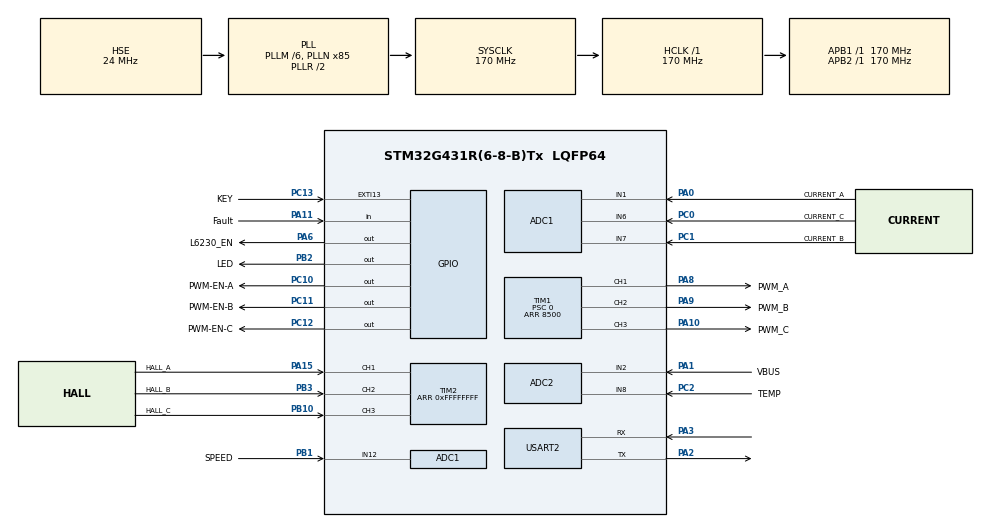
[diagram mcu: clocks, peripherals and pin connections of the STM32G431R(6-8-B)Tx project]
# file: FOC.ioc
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ADC1.Channel-0\#ChannelRegularConversion=ADC_CHANNEL_1
ADC1.Channel-1\#ChannelRegularConversion=ADC_CHANNEL_7
ADC1.Channel-2\#ChannelRegularConversion=ADC_CHANNEL_6
ADC1.Channel-3\#ChannelRegularConversion=ADC_CHANNEL_12
ADC1.ContinuousConvMode=DISABLE
ADC1.DMAContinuousRequests=ENABLE
ADC1.EOCSelection=ADC_EOC_SEQ_CONV
ADC1.ExternalTrigConv=ADC_EXTERNALTRIG_T1_TRGO
ADC1.NbrOfConversion=4
ADC1.NbrOfConversionFlag=1
ADC1.OffsetNumber-0\#ChannelRegularConversion=ADC_OFFSET_NONE
ADC1.OffsetNumber-1\#ChannelRegularConversion=ADC_OFFSET_NONE
ADC1.OffsetNumber-2\#ChannelRegularConversion=ADC_OFFSET_NONE
ADC1.OffsetNumber-3\#ChannelRegularConversion=ADC_OFFSET_NONE
ADC1.Rank-0\#ChannelRegularConversion=1
ADC1.Rank-1\#ChannelRegularConversion=2
ADC1.Rank-2\#ChannelRegularConversion=3
ADC1.Rank-3\#ChannelRegularConversion=4
ADC1.SamplingTime-0\#ChannelRegularConversion=ADC_SAMPLETIME_6CYCLES_5
ADC1.SamplingTime-1\#ChannelRegularConversion=ADC_SAMPLETIME_6CYCLES_5
ADC1.SamplingTime-2\#ChannelRegularConversion=ADC_SAMPLETIME_6CYCLES_5
ADC1.SamplingTime-3\#ChannelRegularConversion=ADC_SAMPLETIME_6CYCLES_5
ADC1.master=1
ADC2.Channel-0\#ChannelRegularConversion=ADC_CHANNEL_2
ADC2.Channel-1\#ChannelRegularConversion=ADC_CHANNEL_8
ADC2.DMAContinuousRequests=ENABLE
ADC2.EOCSelection=ADC_EOC_SEQ_CONV
ADC2.ExternalTrigConv=ADC_EXTERNALTRIG_T1_TRGO
ADC2.NbrOfConversion=2
ADC2.NbrOfConversionFlag=1
ADC2.OffsetNumber-0\#ChannelRegularConversion=ADC_OFFSET_NONE
ADC2.OffsetNumber-1\#ChannelRegularConversion=ADC_OFFSET_NONE
ADC2.Rank-0\#ChannelRegularConversion=1
ADC2.Rank-1\#ChannelRegularConversion=2
ADC2.SamplingTime-0\#ChannelRegularConversion=ADC_SAMPLETIME_6CYCLES_5
ADC2.SamplingTime-1\#ChannelRegularConversion=ADC_SAMPLETIME_6CYCLES_5
Dma.ADC1.0.Direction=DMA_PERIPH_TO_MEMORY
Dma.ADC1.0.EventEnable=DISABLE
Dma.ADC1.0.Instance=DMA1_Channel1
Dma.ADC1.0.MemDataAlignment=DMA_MDATAALIGN_WORD
Dma.ADC1.0.MemInc=DMA_MINC_ENABLE
Dma.ADC1.0.Mode=DMA_CIRCULAR
Dma.ADC1.0.PeriphDataAlignment=DMA_PDATAALIGN_WORD
Dma.ADC1.0.PeriphInc=DMA_PINC_DISABLE
Dma.ADC1.0.Polarity=HAL_DMAMUX_REQ_GEN_RISING
Dma.ADC1.0.Priority=DMA_PRIORITY_LOW
Dma.ADC1.0.RequestNumber=1
Dma.ADC1.0.SignalID=NONE
Dma.ADC1.0.SyncEnable=DISABLE
Dma.ADC1.0.SyncPolarity=HAL_DMAMUX_SYNC_NO_EVENT
Dma.ADC1.0.SyncRequestNumber=1
Dma.ADC1.0.SyncSignalID=NONE
Dma.ADC2.1.Direction=DMA_PERIPH_TO_MEMORY
Dma.ADC2.1.EventEnable=DISABLE
Dma.ADC2.1.Instance=DMA1_Channel2
Dma.ADC2.1.MemDataAlignment=DMA_MDATAALIGN_WORD
Dma.ADC2.1.MemInc=DMA_MINC_ENABLE
Dma.ADC2.1.Mode=DMA_CIRCULAR
Dma.ADC2.1.PeriphDataAlignment=DMA_PDATAALIGN_WORD
Dma.ADC2.1.PeriphInc=DMA_PINC_DISABLE
Dma.ADC2.1.Polarity=HAL_DMAMUX_REQ_GEN_RISING
Dma.ADC2.1.Priority=DMA_PRIORITY_LOW
Dma.ADC2.1.RequestNumber=1
Dma.ADC2.1.SignalID=NONE
Dma.ADC2.1.SyncEnable=DISABLE
Dma.ADC2.1.SyncPolarity=HAL_DMAMUX_SYNC_NO_EVENT
Dma.ADC2.1.SyncRequestNumber=1
Dma.ADC2.1.SyncSignalID=NONE
Dma.CORDIC_READ.3.Direction=DMA_PERIPH_TO_MEMORY
Dma.CORDIC_READ.3.EventEnable=DISABLE
Dma.CORDIC_READ.3.Instance=DMA1_Channel4
Dma.CORDIC_READ.3.MemDataAlignment=DMA_MDATAALIGN_WORD
Dma.CORDIC_READ.3.MemInc=DMA_MINC_ENABLE
Dma.CORDIC_READ.3.Mode=DMA_NORMAL
Dma.CORDIC_READ.3.PeriphDataAlignment=DMA_PDATAALIGN_WORD
Dma.CORDIC_READ.3.PeriphInc=DMA_PINC_DISABLE
Dma.CORDIC_READ.3.Polarity=HAL_DMAMUX_REQ_GEN_RISING
Dma.CORDIC_READ.3.Priority=DMA_PRIORITY_LOW
Dma.CORDIC_READ.3.RequestNumber=1
Dma.CORDIC_READ.3.SignalID=NONE
Dma.CORDIC_READ.3.SyncEnable=DISABLE
Dma.CORDIC_READ.3.SyncPolarity=HAL_DMAMUX_SYNC_NO_EVENT
Dma.CORDIC_READ.3.SyncRequestNumber=1
Dma.CORDIC_READ.3.SyncSignalID=NONE
Dma.CORDIC_WRITE.4.Direction=DMA_MEMORY_TO_PERIPH
Dma.CORDIC_WRITE.4.EventEnable=DISABLE
Dma.CORDIC_WRITE.4.Instance=DMA1_Channel5
Dma.CORDIC_WRITE.4.MemDataAlignment=DMA_MDATAALIGN_WORD
Dma.CORDIC_WRITE.4.MemInc=DMA_MINC_ENABLE
Dma.CORDIC_WRITE.4.Mode=DMA_NORMAL
Dma.CORDIC_WRITE.4.PeriphDataAlignment=DMA_PDATAALIGN_WORD
Dma.CORDIC_WRITE.4.PeriphInc=DMA_PINC_DISABLE
Dma.CORDIC_WRITE.4.Polarity=HAL_DMAMUX_REQ_GEN_RISING
Dma.CORDIC_WRITE.4.Priority=DMA_PRIORITY_LOW
Dma.CORDIC_WRITE.4.RequestNumber=1
Dma.CORDIC_WRITE.4.SignalID=NONE
Dma.CORDIC_WRITE.4.SyncEnable=DISABLE
Dma.CORDIC_WRITE.4.SyncPolarity=HAL_DMAMUX_SYNC_NO_EVENT
Dma.CORDIC_WRITE.4.SyncRequestNumber=1
Dma.CORDIC_WRITE.4.SyncSignalID=NONE
Dma.Request0=ADC1
Dma.Request1=ADC2
Dma.Request2=USART2_TX
Dma.Request3=CORDIC_READ
Dma.Request4=CORDIC_WRITE
Dma.USART2_TX.2.Direction=DMA_MEMORY_TO_PERIPH
Dma.USART2_TX.2.EventEnable=DISABLE
Dma.USART2_TX.2.Instance=DMA1_Channel3
Dma.USART2_TX.2.MemDataAlignment=DMA_MDATAALIGN_BYTE
Dma.USART2_TX.2.MemInc=DMA_MINC_ENABLE
Dma.USART2_TX.2.Mode=DMA_NORMAL
Dma.USART2_TX.2.PeriphDataAlignment=DMA_PDATAALIGN_BYTE
Dma.USART2_TX.2.PeriphInc=DMA_PINC_DISABLE
Dma.USART2_TX.2.Polarity=HAL_DMAMUX_REQ_GEN_RISING
Dma.USART2_TX.2.Priority=DMA_PRIORITY_LOW
Dma.USART2_TX.2.RequestNumber=1
Dma.USART2_TX.2.SignalID=NONE
Dma.USART2_TX.2.SyncEnable=DISABLE
Dma.USART2_TX.2.SyncPolarity=HAL_DMAMUX_SYNC_NO_EVENT
Dma.USART2_TX.2.SyncRequestNumber=1
Dma.USART2_TX.2.SyncSignalID=NONE
Mcu.Family=STM32G4
Mcu.Name=STM32G431R(6-8-B)Tx
Mcu.Package=LQFP64
NVIC.ADC1_2_IRQn=true\:0\:0\:false\:false\:true\:true\:true\:true
NVIC.CORDIC_IRQn=true\:0\:0\:false\:false\:true\:true\:true\:true
NVIC.DMA1_Channel1_IRQn=true\:0\:0\:false\:false\:true\:false\:true\:true
NVIC.DMA1_Channel2_IRQn=true\:0\:0\:false\:false\:true\:false\:true\:true
NVIC.DMA1_Channel3_IRQn=true\:0\:0\:false\:false\:true\:false\:true\:true
NVIC.DMA1_Channel4_IRQn=true\:0\:0\:false\:false\:true\:false\:true\:true
NVIC.DMA1_Channel5_IRQn=true\:0\:0\:false\:false\:true\:false\:true\:true
NVIC.EXTI15_10_IRQn=true\:0\:0\:false\:false\:true\:true\:true\:true
NVIC.PriorityGroup=NVIC_PRIORITYGROUP_4
NVIC.TIM2_IRQn=true\:0\:0\:false\:false\:true\:true\:true\:true
NVIC.USART2_IRQn=true\:0\:0\:false\:false\:true\:true\:true\:true
PA0.GPIO_Label=CURRENT_A
PA0.Mode=IN1-Single-Ended
PA0.Signal=ADC1_IN1
PA1.GPIO_Label=VBUS
PA1.Mode=IN2-Single-Ended
PA1.Signal=ADC2_IN2
PA10.GPIO_Label=PWM_C
PA10.GPIO_PuPd=GPIO_NOPULL
PA10.Signal=S_TIM1_CH3
PA11.GPIO_Label=Fault
PA11.Signal=GPIO_Input
PA13.Mode=Serial_Wire
PA13.Signal=SYS_JTMS-SWDIO
PA14.Mode=Serial_Wire
PA14.Signal=SYS_JTCK-SWCLK
PA15.GPIO_Label=HALL_A
PA15.Signal=S_TIM2_CH1
PA2.Mode=Asynchronous
PA2.Signal=USART2_TX
PA3.Mode=Asynchronous
PA3.Signal=USART2_RX
PA6.GPIO_Label=L6230_EN
PA6.GPIO_ModeDefaultOutputPP=GPIO_MODE_OUTPUT_OD
PA6.GPIO_PuPd=GPIO_NOPULL
PA6.Signal=GPIO_Output
PA8.GPIO_Label=PWM_A
PA8.Signal=S_TIM1_CH1
PA9.GPIO_Label=PWM_B
PA9.Signal=S_TIM1_CH2
PB1.GPIO_Label=SPEED
PB1.Mode=IN12-Single-Ended
PB1.Signal=ADC1_IN12
PB10.GPIO_Label=HALL_C
PB10.Signal=S_TIM2_CH3
PB2.GPIO_Label=LED
PB2.Signal=GPIO_Output
PB3.GPIO_Label=HALL_B
PB3.Signal=S_TIM2_CH2
PC0.GPIO_Label=CURRENT_C
PC0.Mode=IN6-Single-Ended
PC0.Signal=ADC1_IN6
PC1.GPIO_Label=CURRENT_B
PC1.Mode=IN7-Single-Ended
PC1.Signal=ADC1_IN7
PC10.GPIO_Label=PWM-EN-A
PC10.Signal=GPIO_Output
PC11.GPIO_Label=PWM-EN-B
PC11.Signal=GPIO_Output
PC12.GPIO_Label=PWM-EN-C
PC12.Signal=GPIO_Output
PC13.GPIO_Label=KEY
PC13.GPIO_ModeDefaultEXTI=GPIO_MODE_IT_RISING_FALLING
PC13.Signal=GPXTI13
PC14-OSC32_IN.Mode=LSE-External-Oscillator
PC14-OSC32_IN.Signal=RCC_OSC32_IN
PC15-OSC32_OUT.Mode=LSE-External-Oscillator
PC15-OSC32_OUT.Signal=RCC_OSC32_OUT
PC2.GPIO_Label=TEMP
PC2.Mode=IN8-Single-Ended
PC2.Signal=ADC2_IN8
PF0-OSC_IN.Mode=HSE-External-Oscillator
PF0-OSC_IN.Signal=RCC_OSC_IN
PF1-OSC_OUT.Mode=HSE-External-Oscillator
PF1-OSC_OUT.Signal=RCC_OSC_OUT
ProjectManager.HeapSize=0x200
ProjectManager.StackSize=0x400
ProjectManager.TargetToolchain=MDK-ARM V5
RCC.ADC12Freq_Value=170000000
RCC.AHBFreq_Value=170000000
RCC.APB1Freq_Value=170000000
RCC.APB1TimFreq_Value=170000000
RCC.APB2Freq_Value=170000000
RCC.APB2TimFreq_Value=170000000
RCC.CortexFreq_Value=170000000
RCC.EXTERNAL_CLOCK_VALUE=12288000
RCC.HCLKFreq_Value=170000000
RCC.HSE_VALUE=24000000
RCC.HSI48_VALUE=48000000
RCC.HSI_VALUE=16000000
RCC.PLLM=RCC_PLLM_DIV6
RCC.PLLN=85
RCC.PLLSourceVirtual=RCC_PLLSOURCE_HSE
RCC.SYSCLKFreq_VALUE=170000000
RCC.SYSCLKSource=RCC_SYSCLKSOURCE_PLLCLK
RCC.USBFreq_Value=170000000
RCC.VCOOutputFreq_Value=340000000
SH.S_TIM1_CH1.0=TIM1_CH1,PWM Generation1 CH1
SH.S_TIM1_CH2.0=TIM1_CH2,PWM Generation2 CH2
SH.S_TIM1_CH3.0=TIM1_CH3,PWM Generation3 CH3
SH.S_TIM2_CH1.0=TIM2_CH1,Xored_Inputs_Hall_Sensor_Interface
SH.S_TIM2_CH2.0=TIM2_CH2,Xored_Inputs_Hall_Sensor_Interface
SH.S_TIM2_CH3.0=TIM2_CH3,Xored_Inputs_Hall_Sensor_Interface
TIM1.Channel-PWM\ Generation1\ CH1=TIM_CHANNEL_1
TIM1.Channel-PWM\ Generation2\ CH2=TIM_CHANNEL_2
TIM1.Channel-PWM\ Generation3\ CH3=TIM_CHANNEL_3
TIM1.CounterMode=TIM_COUNTERMODE_CENTERALIGNED1
TIM1.OCMode_PWM-PWM\ Generation1\ CH1=TIM_OCMODE_PWM2
TIM1.OCMode_PWM-PWM\ Generation2\ CH2=TIM_OCMODE_PWM2
TIM1.OCMode_PWM-PWM\ Generation3\ CH3=TIM_OCMODE_PWM2
TIM1.PeriodNoDither=8500
TIM1.Prescaler=0
TIM1.RepetitionCounter=1
TIM1.TIM_MasterOutputTrigger=TIM_TRGO_UPDATE
TIM2.PeriodNoDither=0xFFFFFFFF
USART2.VirtualMode-Asynchronous=VM_ASYNC
VP_CORDIC_VS_CORDIC.Mode=CORDIC_Activate
VP_SYS_VS_DBSignals.Mode=DisableDeadBatterySignals
VP_TIM1_VS_ClockSourceINT.Mode=Internal
VP_TIM2_VS_ClockSourceINT.Mode=Internal
board=custom

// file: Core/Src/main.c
/* USER CODE BEGIN Header */
/**
  ******************************************************************************
  * @file           : main.c
  * @brief          : Main program body
  ******************************************************************************
  * @attention
  *
  * Copyright (c) 2024 STMicroelectronics.
  * All rights reserved.
  *
  * This software is licensed under terms that can be found in the LICENSE file
  * in the root directory of this software component.
  * If no LICENSE file comes with this software, it is provided AS-IS.
  *
  ******************************************************************************
  */
/* USER CODE END Header */
#include "main.h"
#include "adc.h"
#include "cordic.h"
#include "dma.h"
#include "tim.h"
#include "usart.h"
#include "gpio.h"

/* USER CODE BEGIN Includes */
#include "foc.h"
#include "stdio.h"
#include "algorithm.h"
#include "usart.h"
#include <stdarg.h>
#include <string.h>
extern UI_3s I_3s;
extern UI_2s I_2s;
extern HFSVI_Structure HFSVI;
extern MOTOR_HandleTypeDef Motor;
/* USER CODE END Includes */

/* USER CODE BEGIN PD */

//float temp[3] = {196.625f,196.625f,196.625f};

/* USER CODE END PD */

void SystemClock_Config(void);

int main(void)
{

  /* MCU Configuration--------------------------------------------------------*/

  /* Reset of all peripherals, Initializes the Flash interface and the Systick. */
  HAL_Init();

  /* Configure the system clock */
  SystemClock_Config();

  /* Initialize all configured peripherals */
  MX_GPIO_Init();
  MX_DMA_Init();
  MX_ADC1_Init();
  MX_TIM1_Init();
  MX_TIM2_Init();
  MX_CORDIC_Init();
  MX_USART2_UART_Init();
  MX_ADC2_Init();
  /* USER CODE BEGIN 2 */
  FocInit();
  /* USER CODE END 2 */

  /* Infinite loop */
  /* USER CODE BEGIN WHILE */
  while (1)
  {
//    printf("%f,%f\n",Motor.I_2r.D,Motor.I_2r.Q,HFSVI.theta);
    /* USER CODE END WHILE */

  }
}

void SystemClock_Config(void)
{
  RCC_OscInitTypeDef RCC_OscInitStruct = {0};
  RCC_ClkInitTypeDef RCC_ClkInitStruct = {0};

  /** Configure the main internal regulator output voltage
  */
  HAL_PWREx_ControlVoltageScaling(PWR_REGULATOR_VOLTAGE_SCALE1_BOOST);

  /** Initializes the RCC Oscillators according to the specified parameters
  * in the RCC_OscInitTypeDef structure.
  */
  RCC_OscInitStruct.OscillatorType = RCC_OSCILLATORTYPE_HSE;
  RCC_OscInitStruct.HSEState = RCC_HSE_ON;
  RCC_OscInitStruct.PLL.PLLState = RCC_PLL_ON;
  RCC_OscInitStruct.PLL.PLLSource = RCC_PLLSOURCE_HSE;
  RCC_OscInitStruct.PLL.PLLM = RCC_PLLM_DIV6;
  RCC_OscInitStruct.PLL.PLLN = 85;
  RCC_OscInitStruct.PLL.PLLP = RCC_PLLP_DIV2;
  RCC_OscInitStruct.PLL.PLLQ = RCC_PLLQ_DIV2;
  RCC_OscInitStruct.PLL.PLLR = RCC_PLLR_DIV2;
  if (HAL_RCC_OscConfig(&RCC_OscInitStruct) != HAL_OK)
  {
    Error_Handler();
  }

  /** Initializes the CPU, AHB and APB buses clocks
  */
  RCC_ClkInitStruct.ClockType = RCC_CLOCKTYPE_HCLK|RCC_CLOCKTYPE_SYSCLK
                              |RCC_CLOCKTYPE_PCLK1|RCC_CLOCKTYPE_PCLK2;
  RCC_ClkInitStruct.SYSCLKSource = RCC_SYSCLKSOURCE_PLLCLK;
  RCC_ClkInitStruct.AHBCLKDivider = RCC_SYSCLK_DIV1;
  RCC_ClkInitStruct.APB1CLKDivider = RCC_HCLK_DIV1;
  RCC_ClkInitStruct.APB2CLKDivider = RCC_HCLK_DIV1;

  if (HAL_RCC_ClockConfig(&RCC_ClkInitStruct, FLASH_LATENCY_4) != HAL_OK)
  {
    Error_Handler();
  }
}

/* USER CODE BEGIN 4 */

int fputc(int ch, FILE *f)

{

  HAL_UART_Transmit(&huart2, (uint8_t *)&ch, 1, 0xffff);

  return ch;
}

/* USER CODE END 4 */

void Error_Handler(void)
{
  __disable_irq();
  while (1)
  {
  }
}
